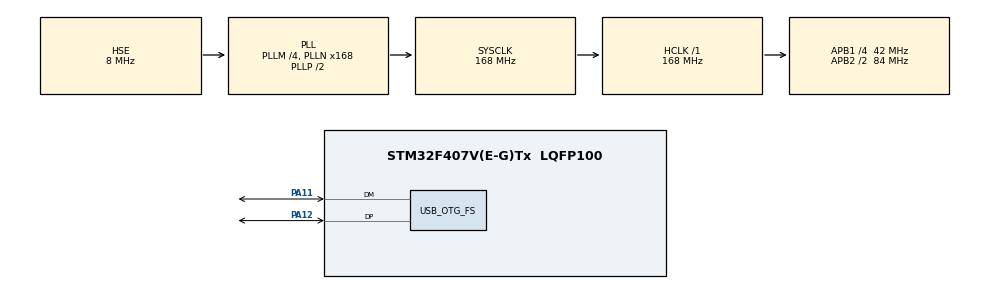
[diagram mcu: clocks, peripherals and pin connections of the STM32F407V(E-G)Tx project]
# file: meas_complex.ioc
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Mcu.Family=STM32F4
Mcu.Name=STM32F407V(E-G)Tx
Mcu.Package=LQFP100
NVIC.OTG_FS_IRQn=true\:0\:0\:false\:false\:true\:false\:true
NVIC.PriorityGroup=NVIC_PRIORITYGROUP_4
PA11.Mode=Device_Only
PA11.Signal=USB_OTG_FS_DM
PA12.Mode=Device_Only
PA12.Signal=USB_OTG_FS_DP
PA13.Mode=Serial_Wire
PA13.Signal=SYS_JTMS-SWDIO
PA14.Mode=Serial_Wire
PA14.Signal=SYS_JTCK-SWCLK
PH0-OSC_IN.Mode=HSE-External-Oscillator
PH0-OSC_IN.Signal=RCC_OSC_IN
PH1-OSC_OUT.Mode=HSE-External-Oscillator
PH1-OSC_OUT.Signal=RCC_OSC_OUT
ProjectManager.HeapSize=0x600
ProjectManager.StackSize=0x400
ProjectManager.TargetToolchain=Makefile
RCC.48MHZClocksFreq_Value=48000000
RCC.AHBFreq_Value=168000000
RCC.APB1CLKDivider=RCC_HCLK_DIV4
RCC.APB1Freq_Value=42000000
RCC.APB1TimFreq_Value=84000000
RCC.APB2CLKDivider=RCC_HCLK_DIV2
RCC.APB2Freq_Value=84000000
RCC.APB2TimFreq_Value=168000000
RCC.CortexFreq_Value=168000000
RCC.HCLKFreq_Value=168000000
RCC.HSE_VALUE=8000000
RCC.HSI_VALUE=16000000
RCC.LSE_VALUE=32768
RCC.PLLM=4
RCC.PLLN=168
RCC.PLLQ=7
RCC.SYSCLKFreq_VALUE=168000000
RCC.SYSCLKSource=RCC_SYSCLKSOURCE_PLLCLK
RCC.VCOOutputFreq_Value=336000000
USB_DEVICE.CLASS_NAME_FS=CDC
USB_DEVICE.VirtualMode-CDC_FS=Cdc
USB_DEVICE.VirtualModeFS=Cdc_FS
USB_OTG_FS.VirtualMode=Device_Only
VP_USB_DEVICE_VS_USB_DEVICE_CDC_FS.Mode=CDC_FS
board=custom

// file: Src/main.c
/* USER CODE BEGIN Header */
/**
  ******************************************************************************
  * @file           : main.c
  * @brief          : Main program body
  ******************************************************************************
  * @attention
  *
  * <h2><center>&copy; Copyright (c) 2020 STMicroelectronics.
  * All rights reserved.</center></h2>
  *
  * This software component is licensed by ST under Ultimate Liberty license
  * SLA0044, the "License"; You may not use this file except in compliance with
  * the License. You may obtain a copy of the License at:
  *                             www.st.com/SLA0044
  *
  ******************************************************************************
  */
/* USER CODE END Header */

#include "main.h"
#include "usb_device.h"

void SystemClock_Config(void);
static void MX_GPIO_Init(void);
/* USER CODE BEGIN PFP */

void Init(void);

/* USER CODE END PFP */

int main(void)
{

  /* MCU Configuration--------------------------------------------------------*/

  /* Reset of all peripherals, Initializes the Flash interface and the Systick. */
  HAL_Init();

  /* Configure the system clock */
  SystemClock_Config();

  /* USER CODE BEGIN SysInit */
  Init();
  HAL_Delay(100);
  /* USER CODE END SysInit */

  /* Initialize all configured peripherals */
  MX_GPIO_Init();
  MX_USB_DEVICE_Init();

  /* Infinite loop */
  while (1)
  {
    __WFI();
  }
}

void SystemClock_Config(void)
{
  RCC_OscInitTypeDef RCC_OscInitStruct = {0};
  RCC_ClkInitTypeDef RCC_ClkInitStruct = {0};

  /** Configure the main internal regulator output voltage
  */
  __HAL_RCC_PWR_CLK_ENABLE();
  __HAL_PWR_VOLTAGESCALING_CONFIG(PWR_REGULATOR_VOLTAGE_SCALE1);
  /** Initializes the CPU, AHB and APB busses clocks
  */
  RCC_OscInitStruct.OscillatorType = RCC_OSCILLATORTYPE_HSE;
  RCC_OscInitStruct.HSEState = RCC_HSE_ON;
  RCC_OscInitStruct.PLL.PLLState = RCC_PLL_ON;
  RCC_OscInitStruct.PLL.PLLSource = RCC_PLLSOURCE_HSE;
  RCC_OscInitStruct.PLL.PLLM = 4;
  RCC_OscInitStruct.PLL.PLLN = 168;
  RCC_OscInitStruct.PLL.PLLP = RCC_PLLP_DIV2;
  RCC_OscInitStruct.PLL.PLLQ = 7;
  if (HAL_RCC_OscConfig(&RCC_OscInitStruct) != HAL_OK)
  {
    Error_Handler();
  }
  /** Initializes the CPU, AHB and APB busses clocks
  */
  RCC_ClkInitStruct.ClockType = RCC_CLOCKTYPE_HCLK|RCC_CLOCKTYPE_SYSCLK
                              |RCC_CLOCKTYPE_PCLK1|RCC_CLOCKTYPE_PCLK2;
  RCC_ClkInitStruct.SYSCLKSource = RCC_SYSCLKSOURCE_PLLCLK;
  RCC_ClkInitStruct.AHBCLKDivider = RCC_SYSCLK_DIV1;
  RCC_ClkInitStruct.APB1CLKDivider = RCC_HCLK_DIV4;
  RCC_ClkInitStruct.APB2CLKDivider = RCC_HCLK_DIV2;

  if (HAL_RCC_ClockConfig(&RCC_ClkInitStruct, FLASH_LATENCY_5) != HAL_OK)
  {
    Error_Handler();
  }
}

static void MX_GPIO_Init(void)
{

  /* GPIO Ports Clock Enable */
  __HAL_RCC_GPIOH_CLK_ENABLE();
  __HAL_RCC_GPIOA_CLK_ENABLE();

}

/* USER CODE BEGIN 4 */

void Init(void)
{
  //PriorityGroupConfig(NVIC_PRIORITYGROUP_4);
  __HAL_RCC_GPIOD_CLK_ENABLE();
  GPIO_InitTypeDef gpioInit = {0};
  gpioInit.Pin = 0xffff;
	gpioInit.Mode = GPIO_MODE_INPUT;
	gpioInit.Pull = GPIO_PULLDOWN;
	gpioInit.Speed = GPIO_SPEED_FREQ_VERY_HIGH;
  HAL_GPIO_Init(SAMPLING_PORT, &gpioInit);

  #ifdef SAMPLING_MANUAL
  __HAL_RCC_GPIOA_CLK_ENABLE();
  GPIO_InitTypeDef gpioInit_b = {0};
	gpioInit_b.Pin = 0x0001;
	gpioInit_b.Mode = GPIO_MODE_AF_PP;
	gpioInit_b.Pull = GPIO_PULLDOWN;
	gpioInit_b.Speed = GPIO_SPEED_FREQ_HIGH;
  gpioInit_b.Alternate = GPIO_AF3_TIM8;
	HAL_GPIO_Init(GPIOA, &gpioInit_b);

	//GPIO_PinAFConfig(GPIOA, GPIO_PinSource0 , GPIO_AF_TIM8);
#endif
}

/* USER CODE END 4 */

void Error_Handler(void)
{
}

/************************ (C) COPYRIGHT STMicroelectronics *****END OF FILE****/
